# neorv32 register map
Vendor: github.com/stnolting/neorv32; Series: RISC-V; File version: 1.12.8
CPU: other r1p0, little endian, MPU, FPU, I-cache, D-cache, ITCM, DTCM, 4 interrupt priority bits
Address unit: 16 bits
Registers are 32-bit, read-write, reset 0x0 unless marked. A register's access mark holds for its fields unless they carry their own. Offsets are from the block's base; [hi:lo] are bit positions.

## TWI — Two-wire interface controller
Base 0xFFF90000
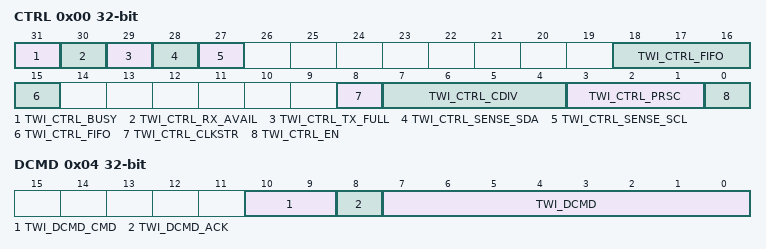
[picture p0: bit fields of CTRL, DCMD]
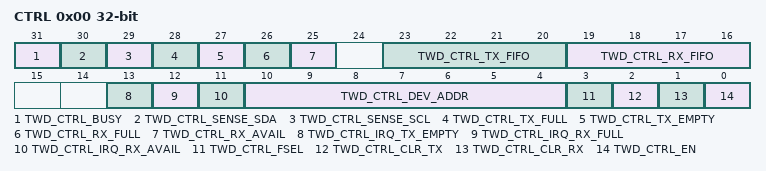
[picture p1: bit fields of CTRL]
0x00 CTRL — Control register
  [31] TWI_CTRL_BUSY ro — Bus engine busy of TX FIFO not empty
  [30] TWI_CTRL_RX_AVAIL ro — RX FIFO not empty (data available)
  [29] TWI_CTRL_TX_FULL ro — TX FIFO full
  [28] TWI_CTRL_SENSE_SDA ro — current state of the SDA bus line
  [27] TWI_CTRL_SENSE_SCL ro — current state of the SCL bus line
  [18:15] TWI_CTRL_FIFO ro — log2(TWI FIFO size)
  [8] TWI_CTRL_CLKSTR — Enable (allow) clock stretching
  [7:4] TWI_CTRL_CDIV — TWI clock divider
  [3:1] TWI_CTRL_PRSC — Clock prescaler select
  [0] TWI_CTRL_EN — TWI enable flag
0x04 DCMD read-modifies — RX/TX data/command register
  [10:9] TWI_DCMD_CMD — Operation command
  [8] TWI_DCMD_ACK — RX = ACK/NACK, TX = MACK
  [7:0] TWI_DCMD — RX/TX data

## TWD — Two-wire device controller
Base 0xFFEA0000
0x00 CTRL — Control register
  [31] TWD_CTRL_BUSY ro — bus engine is busy (transaction in progress)
  [30] TWD_CTRL_SENSE_SDA ro — current state of the SDA bus line
  [29] TWD_CTRL_SENSE_SCL ro — current state of the SCL bus line
  [28] TWD_CTRL_TX_FULL ro — TX FIFO full
  [27] TWD_CTRL_TX_EMPTY ro — TX FIFO empty
  [26] TWD_CTRL_RX_FULL ro — RX FIFO full
  [25] TWD_CTRL_RX_AVAIL ro — RX FIFO data available
  [23:20] TWD_CTRL_TX_FIFO ro — log2(TWD TX FIFO size)
  [19:16] TWD_CTRL_RX_FIFO ro — log2(TWD RX FIFO size)
  [13] TWD_CTRL_IRQ_TX_EMPTY — IRQ if TX FIFO empty
  [12] TWD_CTRL_IRQ_RX_FULL — IRQ if RX FIFO full
  [11] TWD_CTRL_IRQ_RX_AVAIL — IRQ if RX FIFO data available
  [10:4] TWD_CTRL_DEV_ADDR — Device address (7-bit)
  [3] TWD_CTRL_FSEL — Bus sample clock / filter select
  [2] TWD_CTRL_CLR_TX wo — Clear TX FIFO, flag auto-clears
  [1] TWD_CTRL_CLR_RX wo — Clear RX FIFO, flag auto-clears
  [0] TWD_CTRL_EN — TWD enable flag
0x04 DATA read-modifies — RX/TX data register
  [7:0] TWI_DATA — RX/TX data FIFO access

## TRNG — True random number generator
Base 0xFFFA0000
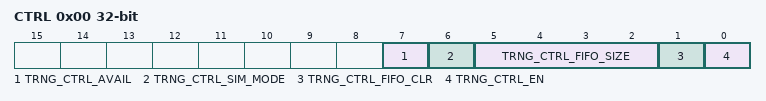
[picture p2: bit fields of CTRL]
0x00 CTRL — Control and data register
  [7] TRNG_CTRL_AVAIL ro — Random data available
  [6] TRNG_CTRL_SIM_MODE ro — TRNG simulation mode (PRNG!) active
  [5:2] TRNG_CTRL_FIFO_SIZE ro — log2(TRNG FIFO size)
  [1] TRNG_CTRL_FIFO_CLR wo — Clear data FIFO when set (flag auto clears)
  [0] TRNG_CTRL_EN — TRNG enable flag
0x04 DATA ro read-modifies — Random data
  [7:0] TRNG_DATA

## WDT — Watchdog timer
Base 0xFFFB0000
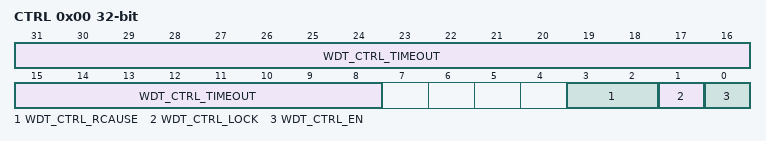
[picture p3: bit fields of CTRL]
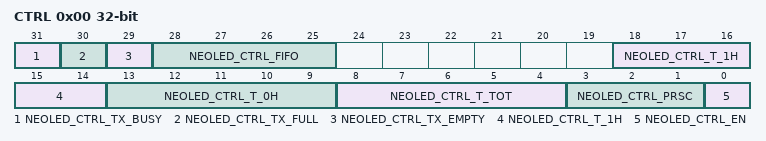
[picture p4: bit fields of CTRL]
0x00 CTRL — Control register
  [31:8] WDT_CTRL_TIMEOUT — Timeout value
  [3:2] WDT_CTRL_RCAUSE ro — Cause of last system reset: 0=external reset, 1=OCD reset, 2=WDT reset, 3=WDT access violation
  [1] WDT_CTRL_LOCK — Lock write access to control register, clears on reset only
  [0] WDT_CTRL_EN — WDT enable flag
0x04 RESET — Watchdog reset register
  [31:0] WDT_RESET wo — Write password to reset/feed the watchdog (0x709D1AB3)

## GPIO — General purpose input/output port
Base 0xFFFC0000
0x00 PORT_IN ro — Parallel input port
0x04 PORT_OUT — Parallel output port
0x10 IRQ_TYPE — Interrupt trigger type (level/edge) for each input pin
0x14 IRQ_POLARITY — Interrupt trigger polarity (rising/falling or high/low) for each input pin
0x18 IRQ_ENABLE — Interrupt enable for each input pin
0x1C IRQ_PENDING — Interrupt pending for each input pin; cleared by writing zero

## NEOLED — Smart LED hardware interface
Base 0xFFFD0000
0x00 CTRL — Control register
  [31] NEOLED_CTRL_TX_BUSY ro — busy flag
  [30] NEOLED_CTRL_TX_FULL ro — TX FIFO is full
  [29] NEOLED_CTRL_TX_EMPTY ro — TX FIFO is empty
  [28:25] NEOLED_CTRL_FIFO ro — log2(TX FIFO size)
  [18:14] NEOLED_CTRL_T_1H — pulse-clock ticks per ONE high-time
  [13:9] NEOLED_CTRL_T_0H — pulse-clock ticks per ZERO high-time
  [8:4] NEOLED_CTRL_T_TOT — pulse-clock ticks per total period bit
  [3:1] NEOLED_CTRL_PRSC — Clock prescaler select
  [0] NEOLED_CTRL_EN — NEOLED enable flag
0x04 DATA24 wo — Send 24-bit data
0x08 DATA32 wo — Send 32-bit data
0x0C STROBE wo — Write any value to send STROBE command
